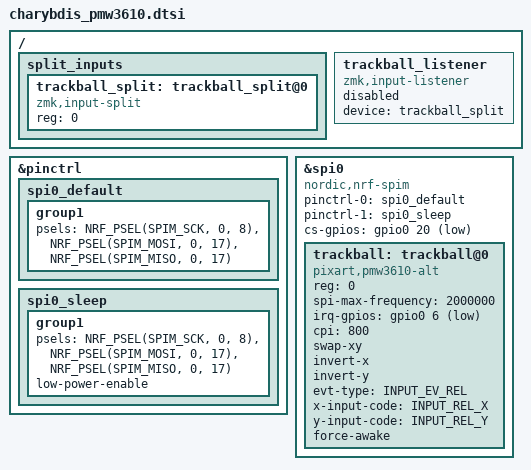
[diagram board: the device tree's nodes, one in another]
#define INPUT_EV_KEY 0x01
#define INPUT_EV_REL 0x02
#define INPUT_EV_ABS 0x03
#define INPUT_EV_MSC 0x04
#define INPUT_EV_VENDOR_START 0xf0
#define INPUT_EV_VENDOR_STOP 0xff

#define INPUT_REL_X 0x00
#define INPUT_REL_Y 0x01
#define INPUT_REL_WHEEL 0x08
#define INPUT_REL_HWHEEL 0x06
#define INPUT_REL_MISC 0x09

&pinctrl {
    spi0_default: spi0_default {
        group1 {
            psels = <NRF_PSEL(SPIM_SCK, 0, 8)>,
                <NRF_PSEL(SPIM_MOSI, 0, 17)>,
                <NRF_PSEL(SPIM_MISO, 0, 17)>;
        };
    };

    spi0_sleep: spi0_sleep {
        group1 {
            psels = <NRF_PSEL(SPIM_SCK, 0, 8)>,
                <NRF_PSEL(SPIM_MOSI, 0, 17)>,
                <NRF_PSEL(SPIM_MISO, 0, 17)>;
            low-power-enable;
        };
    };
};

#include <zephyr/dt-bindings/input/input-event-codes.h>

&spi0 {
    status = "okay";
    compatible = "nordic,nrf-spim";
    pinctrl-0 = <&spi0_default>;
    pinctrl-1 = <&spi0_sleep>;
    pinctrl-names = "default", "sleep";
    cs-gpios = <&gpio0 20 GPIO_ACTIVE_LOW>;

    trackball: trackball@0 {
        status = "okay";
        compatible = "pixart,pmw3610-alt";   /* 关键：从 pmw3610 改为 pmw3610-alt */
        reg = <0>;
        spi-max-frequency = <2000000>;
        irq-gpios = <&gpio0 6 (GPIO_ACTIVE_LOW | GPIO_PULL_UP)>;
        cpi = <800>;
        swap-xy;    /* 原 CONFIG_PMW3610_SWAP_XY，现在移到 dts */
        invert-x;   /* 原 CONFIG_PMW3610_INVERT_X，现在移到 dts */
        invert-y;   /* 原 CONFIG_PMW3610_INVERT_Y，现在移到 dts */
        evt-type = <INPUT_EV_REL>;
        x-input-code = <INPUT_REL_X>;
        y-input-code = <INPUT_REL_Y>;

        force-awake;
        /* ZMK 处于 ACTIVE 状态时保持传感器唤醒，
           进入 IDLE/SLEEP 后回落到正常 downshift 省电模式 */
    };
};

/ {
    split_inputs {
        #address-cells = <1>;
        #size-cells = <0>;

        trackball_split: trackball_split@0 {
            compatible = "zmk,input-split";
            reg = <0>;
        };
    };

    trackball_listener: trackball_listener {
        compatible = "zmk,input-listener";
        status = "disabled"; /* 在 central (右手) overlay 里会 override 成 okay */
        device = <&trackball_split>;
    };
};
